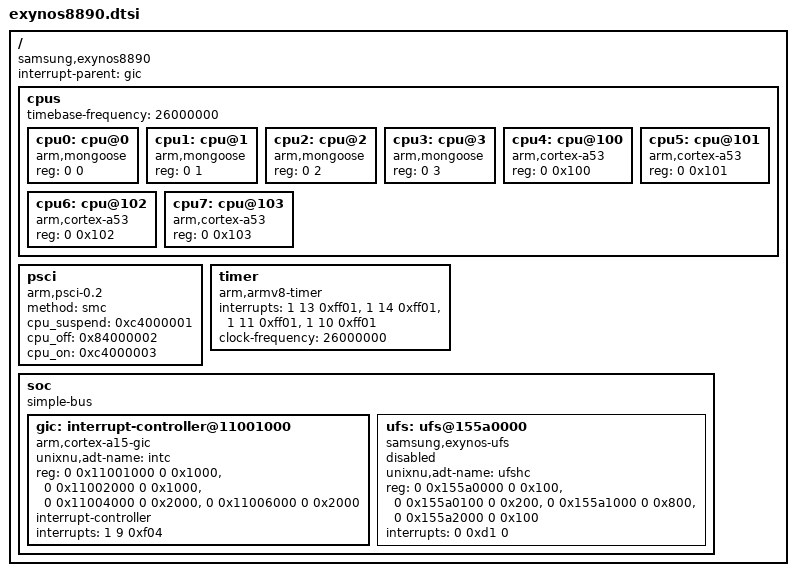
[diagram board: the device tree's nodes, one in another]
// SPDX-License-Identifier: BSD-2-Clause-Patent
//
// Shared Exynos 8890 resources. Values come from the SM-G935F stock boot DTB
// (G935FXXS6ESI4) and are cross-checked against the kernel source in soc.toml.
// Cluster 0 (MPIDR 0x0-0x3) is Mongoose; cluster 1 (MPIDR 0x100-0x103) is
// Cortex-A53. Board memory, reservations and enabled CPUs live in the device
// repository.
/ {
    compatible = "samsung,exynos8890";
    #address-cells = <2>;
    #size-cells = <2>;
    interrupt-parent = <&gic>;

    cpus {
        #address-cells = <2>;
        #size-cells = <0>;
        timebase-frequency = <26000000>;

        cpu0: cpu@0 { device_type = "cpu"; compatible = "arm,mongoose", "arm,armv8"; reg = <0 0>; };
        cpu1: cpu@1 { device_type = "cpu"; compatible = "arm,mongoose", "arm,armv8"; reg = <0 1>; };
        cpu2: cpu@2 { device_type = "cpu"; compatible = "arm,mongoose", "arm,armv8"; reg = <0 2>; };
        cpu3: cpu@3 { device_type = "cpu"; compatible = "arm,mongoose", "arm,armv8"; reg = <0 3>; };
        cpu4: cpu@100 { device_type = "cpu"; compatible = "arm,cortex-a53", "arm,armv8"; reg = <0 0x100>; };
        cpu5: cpu@101 { device_type = "cpu"; compatible = "arm,cortex-a53", "arm,armv8"; reg = <0 0x101>; };
        cpu6: cpu@102 { device_type = "cpu"; compatible = "arm,cortex-a53", "arm,armv8"; reg = <0 0x102>; };
        cpu7: cpu@103 { device_type = "cpu"; compatible = "arm,cortex-a53", "arm,armv8"; reg = <0 0x103>; };
    };

    psci {
        compatible = "arm,psci-0.2";
        method = "smc";
        cpu_suspend = <0xc4000001>;
        cpu_off = <0x84000002>;
        cpu_on = <0xc4000003>;
    };

    timer {
        compatible = "arm,armv8-timer";
        interrupts = <1 13 0xff01>, <1 14 0xff01>, <1 11 0xff01>, <1 10 0xff01>;
        clock-frequency = <26000000>;
    };

    soc {
        compatible = "simple-bus";
        #address-cells = <2>;
        #size-cells = <2>;
        ranges;

        gic: interrupt-controller@11001000 {
            compatible = "arm,cortex-a15-gic";
            unixnu,adt-name = "intc";
            reg = <0 0x11001000 0 0x1000>,
                  <0 0x11002000 0 0x1000>,
                  <0 0x11004000 0 0x2000>,
                  <0 0x11006000 0 0x2000>;
            #interrupt-cells = <3>;
            #address-cells = <0>;
            interrupt-controller;
            interrupts = <1 9 0xf04>;
        };

        ufs: ufs@155a0000 {
            compatible = "samsung,exynos-ufs";
            unixnu,adt-name = "ufshc";
            reg = <0 0x155a0000 0 0x100>,
                  <0 0x155a0100 0 0x200>,
                  <0 0x155a1000 0 0x800>,
                  <0 0x155a2000 0 0x100>;
            interrupts = <0 0xd1 0>;
            status = "disabled";
        };
    };
};
